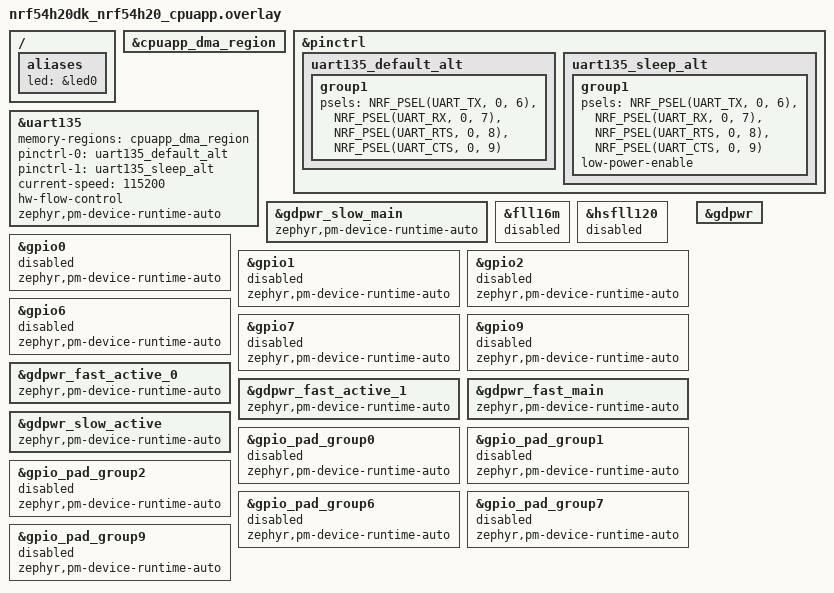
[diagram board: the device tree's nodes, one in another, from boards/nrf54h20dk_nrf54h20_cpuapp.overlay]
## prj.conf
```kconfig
CONFIG_SERIAL=y
CONFIG_MAIN_STACK_SIZE=2048
CONFIG_UART_ASYNC_API=y

CONFIG_PM=y
CONFIG_PM_DEVICE=y
CONFIG_PM_DEVICE_RUNTIME=y
CONFIG_POWEROFF=y

# For nrf54h only, will be ingored for other platforms
CONFIG_PM_S2RAM=y
CONFIG_PM_S2RAM_CUSTOM_MARKING=y

CONFIG_BOOT_BANNER=y
CONFIG_NCS_BOOT_BANNER=y
CONFIG_ASSERT=y

# Enable for debugging purposes only
CONFIG_PRINTK=y
CONFIG_LOG=y
CONFIG_CONSOLE=y
CONFIG_UART_CONSOLE=y
```

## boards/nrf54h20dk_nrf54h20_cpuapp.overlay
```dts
/*
 * Copyright (c) 2025 Nordic Semiconductor ASA
 *
 * SPDX-License-Identifier: LicenseRef-Nordic-5-Clause
 */

/ {
	aliases {
		led = &led0;
		/delete-property/ led1;
	};
};

/delete-node/ &led1;

&cpuapp_dma_region {
	status="okay";
};

/* UART device used for test
 * not the default UART assignment for the LD
 */
&pinctrl {
	uart135_default_alt: uart135_default_alt {
		group1 {
			psels = <NRF_PSEL(UART_TX, 0, 6)>,
				<NRF_PSEL(UART_RX, 0, 7)>,
				<NRF_PSEL(UART_RTS, 0, 8)>,
				<NRF_PSEL(UART_CTS, 0, 9)>;
		};
	};

	uart135_sleep_alt: uart135_sleep_alt {
		group1 {
			psels = <NRF_PSEL(UART_TX, 0, 6)>,
				<NRF_PSEL(UART_RX, 0, 7)>,
				<NRF_PSEL(UART_RTS, 0, 8)>,
				<NRF_PSEL(UART_CTS, 0, 9)>;
			low-power-enable;
		};
	};
};

dut: &uart135 {
	status = "okay";
	memory-regions = <&cpuapp_dma_region>;
	pinctrl-0 = <&uart135_default_alt>;
	pinctrl-1 = <&uart135_sleep_alt>;
	pinctrl-names = "default", "sleep";
	current-speed = <115200>;
	hw-flow-control;
	zephyr,pm-device-runtime-auto;
};

&gdpwr_slow_main {
	zephyr,pm-device-runtime-auto;
};

// Attempts

&fll16m {
	status = "disabled";
};

&hsfll120 {
	status = "disabled";
};

&gpio0 {
	status = "disabled";
	zephyr,pm-device-runtime-auto;
};

&gpio1 {
	status = "disabled";
	zephyr,pm-device-runtime-auto;
};

&gpio2 {
	status = "disabled";
	zephyr,pm-device-runtime-auto;
};

&gpio6 {
	status = "disabled";
	zephyr,pm-device-runtime-auto;
};

&gpio7 {
	status = "disabled";
	zephyr,pm-device-runtime-auto;
};

&gpio9 {
	status = "disabled";
	zephyr,pm-device-runtime-auto;
};

&gdpwr {
	status = "okay";
};

&gdpwr_fast_active_0 {
	status = "okay";
	zephyr,pm-device-runtime-auto;
};

&gdpwr_fast_active_1 {
	status = "okay";
	zephyr,pm-device-runtime-auto;
};

&gdpwr_fast_main {
	status = "okay";
	zephyr,pm-device-runtime-auto;
};

&gdpwr_slow_active {
	status = "okay";
	zephyr,pm-device-runtime-auto;
};

&gdpwr_slow_main {
	status = "okay";
	zephyr,pm-device-runtime-auto;
};

&gpio_pad_group0 {
	status = "disabled";
	zephyr,pm-device-runtime-auto;
};

&gpio_pad_group1 {
	status = "disabled";
	zephyr,pm-device-runtime-auto;
};

&gpio_pad_group2 {
	status = "disabled";
	zephyr,pm-device-runtime-auto;
};

&gpio_pad_group6 {
	status = "disabled";
	zephyr,pm-device-runtime-auto;
};

&gpio_pad_group7 {
	status = "disabled";
	zephyr,pm-device-runtime-auto;
};

&gpio_pad_group9 {
	status = "disabled";
	zephyr,pm-device-runtime-auto;
};
```

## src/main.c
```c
/*
 * Copyright (c) 2025 Nordic Semiconductor ASA
 *
 * SPDX-License-Identifier: LicenseRef-Nordic-5-Clause
 */

#include <zephyr/drivers/uart.h>
#include <zephyr/pm/device_runtime.h>
#include <zephyr/pm/device.h>
#include <zephyr/kernel.h>
#include <zephyr/logging/log.h>
#include <zephyr/drivers/gpio.h>

/* Note: logging is normally disabled for this test
 * Enable only for debugging purposes
 */
LOG_MODULE_REGISTER(uarte_suspend);

static const struct gpio_dt_spec led = GPIO_DT_SPEC_GET(DT_ALIAS(led), gpios);

#if DT_NODE_EXISTS(DT_NODELABEL(dut))
#define UART_NODE DT_NODELABEL(dut)
#else
#error Improper device tree configuration, UARTE test node not available
#endif

#define UART_ACTION_BASE_TIMEOUT_US 1000
#define TEST_BUFFER_LEN		    10

static const struct device *const uart_dev = DEVICE_DT_GET(UART_NODE);
static const struct device *const uart_dev_gdpwr = DEVICE_DT_GET(DT_NODELABEL(gdpwr_slow_active));
static const struct device *const gpio_dev_gdpwr = DEVICE_DT_GET(DT_NODELABEL(gdpwr_slow_main));

const uint8_t test_pattern[TEST_BUFFER_LEN] = {0x11, 0x12, 0x13, 0x14, 0x15,
					       0x16, 0x17, 0x18, 0x19, 0x20};
static uint8_t test_buffer[TEST_BUFFER_LEN];
static volatile uint8_t uart_error_counter;

/*
 * Callback function for UART async transmission
 */
static void async_uart_callback(const struct device *dev, struct uart_event *evt, void *user_data)
{
	printk("Callback !\n");
	switch (evt->type) {
	case UART_TX_DONE:
		printk("UART_TX_DONE\n");
		break;
	case UART_TX_ABORTED:
		printk("UART_TX_ABORTED\n");
		printk("Callback should not enter here\n");
		__ASSERT_NO_MSG(1 == 0);
		break;
	case UART_RX_RDY:
		printk("UART_RX_RDY\n");
		for (int index = 0; index < TEST_BUFFER_LEN; index++) {
			printk("test_pattern[%d]=%d\n", index, test_pattern[index]);
			printk("test_buffer[%d]=%d\n", index, test_buffer[index]);
			if (test_buffer[index] != test_pattern[index]) {
				printk("Recieived data byte %d does not match pattern 0x%x != "
				       "0x%x\n",
				       index, test_buffer[index], test_pattern[index]);
				__ASSERT_NO_MSG(test_buffer[index] == test_pattern[index]);
			}
		}
		break;
	case UART_RX_BUF_RELEASED:
		printk("UART_RX_BUF_RELEASED\n");
		break;
	case UART_RX_BUF_REQUEST:
		printk("UART_RX_BUF_REQUEST\n");
		break;
	case UART_RX_DISABLED:
		printk("UART_RX_DISABLED\n");
		break;
	default:
		break;
	}
}

/* Helper function for enabling UART RX */
void enable_uart_rx(void)
{
	int err;

	printk("Enable UART RX\n");
	err = uart_rx_enable(uart_dev, test_buffer, TEST_BUFFER_LEN,
			     5 * UART_ACTION_BASE_TIMEOUT_US);
	if (err != 0) {
		printk("Unexpected error when enabling UART RX: %d\n", err);
	}
}

/* Helper function for disabling UART RX */
void disable_uart_rx(void)
{
	int err;

	k_busy_wait(250000);
	printk("Disable UART RX\n");
	err = uart_rx_disable(uart_dev);
	if (err != 0) {
		printk("Unexpected error when disabling RX: %d\n", err);
	}
	k_busy_wait(250000);
}

int main(void)
{
	int err;

	err = gpio_is_ready_dt(&led);
	__ASSERT(err, "Error: GPIO Device not ready");

	err = gpio_pin_configure_dt(&led, GPIO_OUTPUT_ACTIVE);
	__ASSERT(err == 0, "Could not configure led GPIO");

	printk("Hello World! %s\n", CONFIG_BOARD_TARGET);
	printk("UART instance: %s\n", uart_dev->name);
	k_msleep(250);

	err = uart_callback_set(uart_dev, async_uart_callback, NULL);
	if (err != 0) {
		printk("Unexpected error when setting callback %d\n", err);
		__ASSERT_NO_MSG(err == 0);
	}

	while (1) {
		printk("Hello\n");
		enable_uart_rx();

		printk("UART test transmission\n");
		err = uart_tx(uart_dev, test_pattern, TEST_BUFFER_LEN, UART_ACTION_BASE_TIMEOUT_US);
		if (err != 0) {
			printk("Unexpected error when sending UART TX data: %d\n", err);
			__ASSERT_NO_MSG(err == 0);
		}
		disable_uart_rx();
		err = pm_device_action_run(uart_dev, PM_DEVICE_ACTION_SUSPEND);
		printk("Good night\n");
		gpio_pin_set_dt(&led, 0);
		// Comment both pm_device_action_run() to see 13 uA idle current
		err = pm_device_action_run(uart_dev_gdpwr, PM_DEVICE_ACTION_SUSPEND);
		err = pm_device_action_run(gpio_dev_gdpwr, PM_DEVICE_ACTION_SUSPEND);
		k_msleep(1000);
		// Comment both pm_device_action_run() to see 13 uA idle current
		err = pm_device_action_run(gpio_dev_gdpwr, PM_DEVICE_ACTION_RESUME);
		err = pm_device_action_run(uart_dev_gdpwr, PM_DEVICE_ACTION_RESUME);
		gpio_pin_set_dt(&led, 1);
		err = pm_device_action_run(uart_dev, PM_DEVICE_ACTION_RESUME);
	}

	return 0;
}
```
